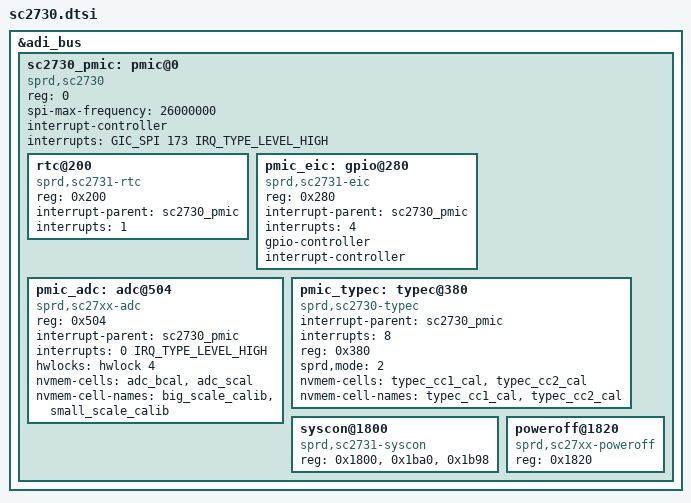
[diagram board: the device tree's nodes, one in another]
// SPDX-License-Identifier: (GPL-2.0+ OR MIT)
/*
 * Unisoc SC2730 PMIC dts file
 *
 * Copyright (C) 2020, Unisoc Inc.
 *
 */


&adi_bus {
	sc2730_pmic: pmic@0 {
		compatible = "sprd,sc2730";
		reg = <0>;
		spi-max-frequency = <26000000>;
		interrupt-controller;
		#interrupt-cells = <1>;
		interrupts = <GIC_SPI 173 IRQ_TYPE_LEVEL_HIGH>;
		#address-cells = <1>;
		#size-cells = <0>;

		rtc@200 {
			compatible = "sprd,sc2731-rtc", "sprd,sc2730-rtc";
			reg = <0x200>;
			interrupt-parent = <&sc2730_pmic>;
			interrupts = <1>;
		};

		pmic_eic: gpio@280 {
			compatible = "sprd,sc2731-eic", "sprd,sc2730-eic";
			reg = <0x280>;
			interrupt-parent = <&sc2730_pmic>;
			interrupts = <4>;
			gpio-controller;
			#gpio-cells = <2>;
			interrupt-controller;
			#interrupt-cells = <2>;
		};

		pmic_adc: adc@504 {
			compatible = "sprd,sc27xx-adc", "sprd,sc2730-adc";
			reg = <0x504>;
			interrupt-parent = <&sc2730_pmic>;
			interrupts = <0 IRQ_TYPE_LEVEL_HIGH>;
			#io-channel-cells = <1>;
			hwlocks = <&hwlock 4>;
			nvmem-cells = <&adc_bcal>, <&adc_scal>;
			nvmem-cell-names = "big_scale_calib", "small_scale_calib";
		};

		pmic_typec: typec@380 {
			compatible = "sprd,sc2730-typec", "sprd,sc27xx-typec";
			interrupt-parent = <&sc2730_pmic>;
			interrupts = <8>;
			reg = <0x380>;
			sprd,mode = <2>;
			nvmem-cells = <&typec_cc1_cal>, <&typec_cc2_cal>;
			nvmem-cell-names = "typec_cc1_cal", "typec_cc2_cal";
			status = "okay";
		};

		syscon@1800 {
			compatible = "sprd,sc2731-syscon", "sprd,sc27xx-syscon";
			reg = <0x1800>, <0x1ba0>, <0x1b98>;
		};
		poweroff@1820 {
			compatible = "sprd,sc27xx-poweroff", "sprd,sc2730-poweroff";
			reg = <0x1820>;
		};
	};
};

#include "efuse.dtsi"
#include "regulator.dtsi"
